# TC35680 register map
Vendor: Toshiba Electronic Devices and Storage Corporation; File version: 0.1
CPU: CM0 r0p0, little endian, no MPU, no FPU, 4 interrupt priority bits
Registers are 32-bit, read-write, no defined reset value unless marked. A register's access mark holds for its fields unless they carry their own. Offsets are from the block's base; [hi:lo] are bit positions.

## SPI1 — Serial Peripheral Interface(Master/Slave)
Base 0x40046000
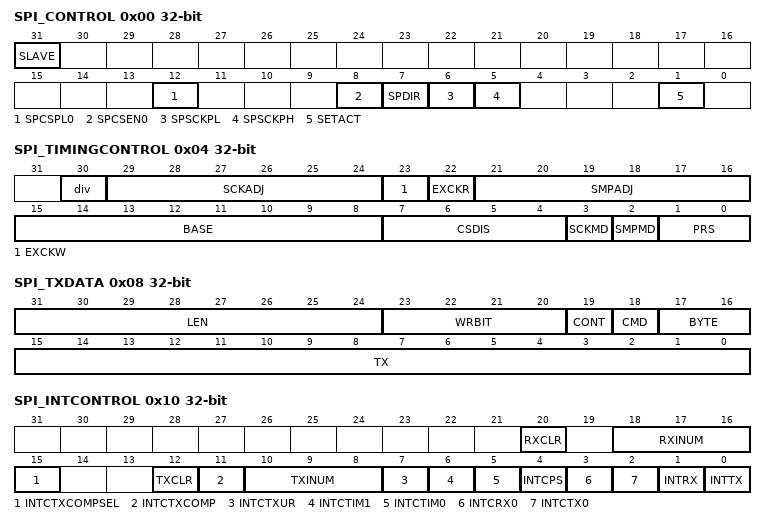
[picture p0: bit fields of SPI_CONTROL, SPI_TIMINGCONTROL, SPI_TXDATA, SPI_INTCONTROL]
0x00 SPI_CONTROL
  [31] SLAVE — Set master/slave mode (R/W). 0: Master mode (default). 1: Slave mode
  [12] SPCSPL0 — Set CS polarity (R/W). 0: Low active (default). 1: High active
  [8] SPCSEN0 — Enable CS (R/W). 0: Disable. 1: Enable (default)
  [7] SPDIR — Specify LSB/MSB first (R/W). 0: MSB first (default). 1: LSB first
  [6] SPSCKPL — Specify serial clock polarity (R/W). 0: Sampling at high (default). 1: Sampling at low
  [5] SPSCKPH — Specify serial clock phase (R/W). 0: Sampling at the first edge (default). 1: Sampling at the second edge
  [1] SETACT — Set operation mode (R/W). 0: Configuration mode. 1: Active mode (default)
0x04 SPI_TIMINGCONTROL
  [30] div — Change the division setting.
  [29:24] SCKADJ — Serial Clock Adjustment. Set a value less than [15:8]. 0: Forbidden. 1-63: settingvalue
  [23] EXCKW — Set Write clock extension. SCK will be output after the deassert of CS. The duration is set on [7:4]. 0: Disable clock extension. 1: Enable clock extension.
  [22] EXCKR — SCK will be output after the deassert of CS. The duration is set on [7:4]. 0: Disable clock extension. 1: Enable clock extension.
  [21:16] SMPADJ — Sampling clock adjustment. 0: forbidden. 1-63: setting value
  [15:8] BASE — Frequency divider. 0: Forbidden. 1-255: value
  [7:4] CSDIS — Chip Select disable parameter. If set, CS will be deasserted at least clock*(this value +1). 0: No deassert. 1-15: Deassert
  [3] SCKMD — Serial Clock Mode. Enable/Disable Serial Clock modulation mode. 0: Disabled. 1: Enabled
  [2] SMPMD — Sampling Modulation Mode.HOGEHOHGEOHGOHOGEHOGH
  [1:0] PRS — Pre-Scaler Setting. 00: Communication clock x 1/1. 01: Communication clock x 1/2. 10: Communication clock x 1/4. 11: Communication clock x 1/8
0x08 SPI_TXDATA
  [31:24] LEN — Default value is zero. When CMD is write (bit[18] = 0), set TX options (R/W). bit[31:26] Reserved bit[25] SPI DO polarity (0: L, 1: H) bit[24] SPI DO output status (0: keep the last data, 1: output H/L set at bit 25). When CMD is read (bit[18] = 1), set RX data length (R/W). bit[31:24] RX data length (unit is defined at bit[17:16])
  [23:20] WRBIT — Set valid TX bit length (R/W). 0x0: The setting at bit[17:16] is applied (default). 0x1: 1 bit. 0x2: 2 bit. ... 0xF: 15 bit
  [19] CONT — Set continuous transfer (R/W). 0: Deassert CS per word (default). 1: Keep CS between words
  [18] CMD — Set transfer command (R/W). 0: Write (default). 1: Read
  [17:16] BYTE — Set transfer byte length (R/W). 00: 1 byte (default). 01: 2 bytes. 10: 3 bytes (valid for read). 11: 4 bytes (valid for read)
  [15:0] TX — Set TX data (R/W) Default value is zero.
0x0C SPI_RXDATA ro
  [31:0] RX — Get RX data (R). When data is 24 bit length, [31:24] = 0x00 (default). When data is 16 bit length, [31:16] = 0x0000. When data is 8 bit length, [31:8] = 0x000000.
0x10 SPI_INTCONTROL — SPI intrrupt control
  [20] RXCLR — Clear RX FIFO (R/W). 0: Do not clear (default). 1: Clear After claer, this register becomes 0.
  [18:16] RXINUM — Watermark for Rx FIFO interrupt. 000: more than 1 data. 001: more than 2 data. 010: more than 3 data. 011: more than 4 data. 100: more than 5 data. 101: more than 6 data. 110: more than 7 data. 111: more than 8 data
  [15] INTCTXCOMPSEL — Tx complete interrupt select bit. Selects the interrupt for bit 10 of interrupt status register. 0: SPI Tx complete status. 1: SPI Tx complete including SPI DMA TX
  [12] TXCLR — Clear TX FIFO (R/W). 0: Do not clear (default). 1: Clear After claer, this register becomes 0.
  [11] INTCTXCOMP — Set Tx complete interrupt. 0: Disable interrupt. 1: Enable interrupt
  [10:8] TXINUM — Water mark for TX FIFO interrupt. 000: more than 1 data. 001: more than 2 data. 010: more than 3 data. 011: more than 4 data. 100: more than 5 data. 101: more than 6 data. 110: more than 7 data. 111: more than 8 data
  [7] INTCTXUR — Serial Under-run interrupt. 0: Disable interrupt. 1: Enable interrupt.
  [6] INTCTIM1 — Serial Tx Wait timer1 interrupt. 0: Disable interrupt. 1: Enable interrupt.
  [5] INTCTIM0 — Serial Tx Wait timer 0 interrupt. 0: Disable interrupt. 1: Enable interrupt.
  [4] INTCPS — Serial Tx Complete interrupt. 0: Disable interrupt. 1: Enable interrupt.
  [3] INTCRX0 — RX FIFO Overrun interrupt. 0: Disable interrupt. 1: Enable interrupt.
  [2] INTCTX0 — TX FIFO Overrun interrupt. 0: Disable interrupt. 1: Enable interrupt.
  [1] INTRX — RX FIFO interrupt. Asserted when there are datas more than [18:16]. 0: Disable interrupt. 1: Enable interrupt.
  [0] INTTX — TX FIFO interrupt. Asserted when there are datas more than [10:8]. 0: Disable interrupt. 1: Enable interrupt.
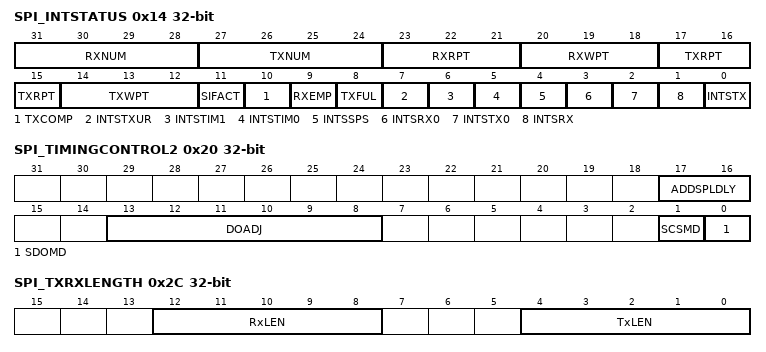
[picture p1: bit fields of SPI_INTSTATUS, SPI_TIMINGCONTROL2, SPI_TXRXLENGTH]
0x14 SPI_INTSTATUS — SPI interrupt status
  [31:28] RXNUM ro — Read deta length in RX FIFO (R). 0000: 0 (default). 0001: 1. ... 0111: 7. 1000: 8. Others: Don't care
  [27:24] TXNUM ro — Read deta length in TX FIFO (R). 0000: 0 (default). 0001: 1. ... 0111: 7. 1000: 8. Others: Don't care
  [23:21] RXRPT — Rx FIFO Read pointer info
  [20:18] RXWPT — Rx FIFO Write pointer info
  [17:15] TXRPT — Tx FIFO Read pointer info
  [14:12] TXWPT — Tx FIFO Read pointer info
  [11] SIFACT ro — Read the status of serial interface (R). 0: Idle (default). 1: Operating
  [10] TXCOMP — Read the status of TX complete interrupt. 0: Exists Interrupt factor. 1: No Interrupt factor.
  [9] RXEMP ro — Read the status of RX FIFO (R). 0: RX FIFO is empty. 1: RX FIFO is not empty.
  [8] TXFUL ro — Read the status of TX FIFO (R). 0: TX FIFO is full. 1: TX FIFO is not full.
  [7] INTSTXUR — Reads Tx Underrun interrupt status. Write 1 to clear. Write 0 is don't care. 0: No interrupt. 1: Interrupt exist.
  [6] INTSTIM1 — Reads Tx Wait timer1 interrupt status. Write 1 to clear. Write 0 is don't care. 0: No interrupt. 1: Interrupt exist.
  [5] INTSTIM0 — Reads Tx Wait timer0 interrupt status. Write 1 to clear. Write 0 is don't care. 0: No interrupt. 1: Interrupt exist.
  [4] INTSSPS — Reads Tx send complete interrupt status. Write 1 to clear. Write 0 is don't care. 0: No interrupt. 1: Interrupt exist.
  [3] INTSRX0 — Reads Rx Fifo Overrun interrupt status. Write 1 to clear. Write 0 is don't care. 0: No interrupt. 1: Interrupt exist.
  [2] INTSTX0 — Reads Tx Fifo Overrun interrupt. Write 1 to clear. Write 0 is don't care. 0: No interrupt. 1: Interrupt exist.
  [1] INTSRX — Reads Rx FIFO interrupt. Write 1 to clear. Write 0 is don't care. 0: No interrupt. 1: Interrupt exist.
  [0] INTSTX — Reads Tx FIFO interrupt. Write 1 to clear. Write 0 is don't care. 0: No interrupt. 1: Interrupt exist.
0x20 SPI_TIMINGCONTROL2 — SPI timing control
  [17:16] ADDSPLDLY — Add sampling delay of RX data (R/W). 01: 1 clk delay (fixed)
  [13:8] DOADJ — Adjust Serial data and chip select. 0: No adjustment. Other: value
  [1] SCSMD — Chip Select output adjust timing enable/disable. 0: disable. 1: enable
  [0] SDOMD — Seriaou output adjust enable/disable. 0: Disable. 1: Enable
0x24 SPI_TXWAITTIMER0 — SPI Wait Timer 0
  [19:0] TIM0B — Value for Tx Waittimer0.
0x28 SPI_TXWAITTIMER1 — SPI Wait Timer 1
  [19:0] TIM1B — Value for Tx Waittimer1.
0x2C SPI_TXRXLENGTH — SPI Data Langth
  [12:8] RxLEN — Set the length of Rx data length. 00-02: Forbidden. 03: 4bit. 04: 5bit. ... 1E:31bit. 1F:32bit
  [4:0] TxLEN — Set the length of Tx data length. 00-02: Forbidden. 03: 4bit. 04: 5bit. ... 1E: 31bit. 1F: 32bit

## SPI2 — Serial Peripheral Interface(Master/Slave)
Base 0x40056000
Registers as SPI1; these are added or differ:
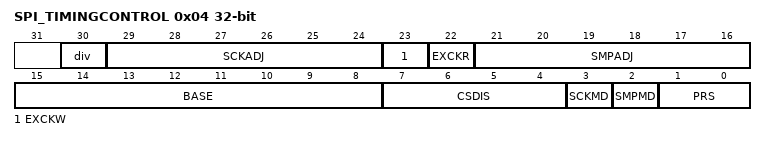
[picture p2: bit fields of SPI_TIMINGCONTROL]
0x04 SPI_TIMINGCONTROL
  [30] div — Change the division setting.
  [29:24] SCKADJ — Serial Clock Adjustment. Set a value less than [15:8]. 0: Forbidden. 1-63: settingvalue
  [23] EXCKW — Set Write clock extension. SCK will be output after the deassert of CS. The duration is set on [7:4]. 0: Disable clock extension. 1: Enable clock extension.
  [22] EXCKR — SCK will be output after the deassert of CS. The duration is set on [7:4]. 0: Disable clock extension. 1: Enable clock extension.
  [21:16] SMPADJ — Sampling clock adjustment. 0: forbidden. 1-63: setting value
  [15:8] BASE — Frequency divider. 0: Forbidden. 1-255: value
  [7:4] CSDIS — Chip Select disable parameter. If set, CS will be deasserted at least clock*(this value +1). 0: No deassert. 1-15: Deassert
  [3] SCKMD — Serial Clock Mode. Enable/Disable Serial Clock modulation mode. 0: Disabled. 1: Enabled
  [2] SMPMD — Sampling Modulation Mode.
  [1:0] PRS — Pre-Scaler Setting. 00: Communication clock x 1/1. 01: Communication clock x 1/2. 10: Communication clock x 1/4. 11: Communication clock x 1/8
